AUTOSAR XML (schema 4-2-2)
package /LedBlinkerApplicationLayer/CompositionPackage
  composition sw component type RootComposition
    component ledBlinkerSWC: type=LedBlinkerSWC
    component serviceIoHwAb: type=IoHwAb
    connect serviceIoHwAb.Digital_LED1 -> ledBlinkerSWC.Digital_LED1
package /LedBlinkerApplicationLayer/ApplicationPackage
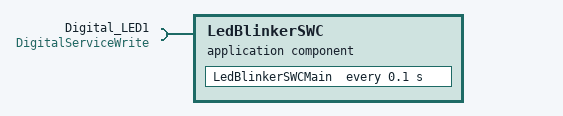
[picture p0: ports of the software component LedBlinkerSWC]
  application sw component type LedBlinkerSWC
    require port Digital_LED1: required-interface=DigitalServiceWrite
    behavior LedBlinkerSWCBehaviour: handle-termination-and-restart=NO-SUPPORT
      timing event LedBlinkerSWCMain_timingEvent_0_1: start-on-event=LedBlinkerSWCMain, period=0.1
      runnable LedBlinkerSWCMain: symbol=ledBlinkerSWCMain
        sync call LED1CallPoint: operation=Digital_LED1.Write, timeout=0.0
  swc implementation LedBlinkerSWCImpl: programming-language=C, vendor-id=0, behavior=LedBlinkerSWCBehaviour
    code-descriptors:
      code src: artifact-descriptors=autosar-engineering-object={short-label=artifactDescriptor, category=artifactDescriptorCategory}
    resource consumption resourceConsumption
package /LedBlinkerApplicationLayer/EcuExtract
  system LedBlinkerEcuExtract: category=ECU_EXTRACT, system-version=1
    system mapping ImplementationMappings
      sw-impl-mappings:
        swc to impl mapping MySWCMap: component-implementation=LedBlinkerSWCImpl, component=RootSwComposition.ledBlinkerSWC
        swc to impl mapping IoHwAbMap: component-implementation=IoHwAbImpl, component=RootSwComposition.serviceIoHwAb
    root-software-compositions:
      root sw composition prototype RootSwComposition: software-composition=RootComposition
package /LedBlinkerBSWConfiguration/Services/Os
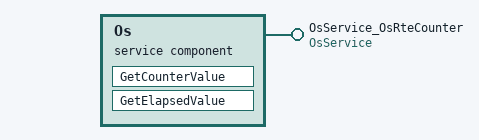
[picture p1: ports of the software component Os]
  service sw component type Os
    provide port OsService_OsRteCounter: provided-interface=OsService
    behavior OsBehavior: handle-termination-and-restart=NO-SUPPORT, port-api-option{port-defined-argument-value{value=CounterType:0, value-type=CounterType}, port=OsService_OsRteCounter}
      operation invoked event GetCounterValue_OsService_OsRteCounter_GetCounterValue: start-on-event=GetCounterValue, operation=OsService_OsRteCounter.GetCounterValue
      operation invoked event GetElapsedValue_OsService_OsRteCounter_GetElapsedValue: start-on-event=GetElapsedValue, operation=OsService_OsRteCounter.GetElapsedValue
      runnable GetCounterValue: symbol=Os_GetCounterValue
      runnable GetElapsedValue: symbol=Os_GetElapsedValue
  swc implementation OsImpl: programming-language=C, vendor-id=60, behavior=OsBehavior
    code-descriptors:
      code src: artifact-descriptors=autosar-engineering-object={short-label=artifactDescriptor, category=artifactDescriptorCategory}
    resource consumption resourceConsumption
package /LedBlinkerBSWConfiguration/Services/IoHwAb
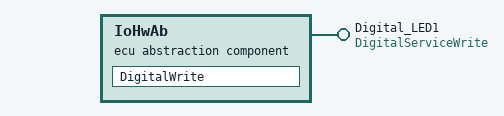
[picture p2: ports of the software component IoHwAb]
  ecu abstraction sw component type IoHwAb
    provide port Digital_LED1: provided-interface=DigitalServiceWrite
    behavior IoHwAbBehavior: handle-termination-and-restart=NO-SUPPORT, port-api-option{port-defined-argument-value{value=IoHwAb_SignalType_:0, value-type=IoHwAb_SignalType_}, port=Digital_LED1}
      operation invoked event DigitalWrite_Digital_LED1_Write: start-on-event=DigitalWrite, operation=Digital_LED1.Write
      runnable DigitalWrite: can-be-invoked-concurrently=true, symbol=IoHwAb_Digital_Write
  swc implementation IoHwAbImpl: programming-language=C, vendor-id=60, behavior=IoHwAbBehavior
    code-descriptors:
      code src: artifact-descriptors=autosar-engineering-object={short-label=artifactDescriptor, category=artifactDescriptorCategory}
    resource consumption resourceConsumption
package /LedBlinkerBSWConfiguration/Services/Det
  service sw component type Det
    behavior DetBehavior: handle-termination-and-restart=NO-SUPPORT
      runnable ReportError: symbol=Det_ReportError
  swc implementation DetImpl: programming-language=C, vendor-id=60, behavior=DetBehavior
    code-descriptors:
      code src: artifact-descriptors=autosar-engineering-object={short-label=artifactDescriptor, category=artifactDescriptorCategory}
    resource consumption resourceConsumption
package /LedBlinkerBSWConfiguration/Services/EcuM
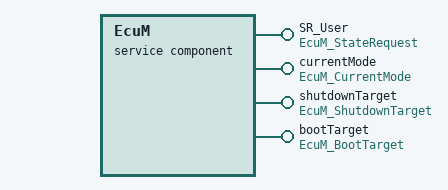
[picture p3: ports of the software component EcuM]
  service sw component type EcuM
    4 x provide port:
      SR_User: provided-interface=EcuM_StateRequest
      currentMode: provided-interface=EcuM_CurrentMode
      shutdownTarget: provided-interface=EcuM_ShutdownTarget
      bootTarget: provided-interface=EcuM_BootTarget
    behavior EcuMFixedBehavior: data-type-mapping=EcuMFixedTypeMappings, handle-termination-and-restart=NO-SUPPORT, port-api-option{port-defined-argument-value{value=EcuM_UserType:0, value-type=EcuM_UserType}, port=SR_User}
      9 x operation invoked event:
        RequestRUN_SR_User_RequestRUN: start-on-event=RequestRUN, operation=SR_User.RequestRUN
        ReleaseRUN_SR_User_ReleaseRUN: start-on-event=ReleaseRUN, operation=SR_User.ReleaseRUN
        RequestPOSTRUN_SR_User_RequestPOSTRUN: start-on-event=RequestPOSTRUN, operation=SR_User.RequestPOSTRUN
        ReleasePOSTRUN_SR_User_ReleasePOSTRUN: start-on-event=ReleasePOSTRUN, operation=SR_User.ReleasePOSTRUN
        SelectShutdownTarget_shutdownTarget_SelectShutdownTarget: start-on-event=SelectShutdownTarget, operation=shutdownTarget.SelectShutdownTarget
        GetShutdownTarget_shutdownTarget_GetShutdownTarget: start-on-event=GetShutdownTarget, operation=shutdownTarget.GetShutdownTarget
        GetLastShutdownTarget_shutdownTarget_GetLastShutdownTarget: start-on-event=GetLastShutdownTarget, operation=shutdownTarget.GetLastShutdownTarget
        SelectBootTarget_bootTarget_SelectBootTarget: start-on-event=SelectBootTarget, operation=bootTarget.SelectBootTarget
        GetBootTarget_bootTarget_GetBootTarget: start-on-event=GetBootTarget, operation=bootTarget.GetBootTarget
      10 x runnable:
        EcuM_MainFunction
          mode switch point modeSwitchPoint_EcuM_MainFunction_currentMode_currentMode: mode-group=currentMode.currentMode
        RequestRUN: can-be-invoked-concurrently=true, symbol=EcuM_RequestRUN
        ReleaseRUN: can-be-invoked-concurrently=true, symbol=EcuM_ReleaseRUN
        RequestPOSTRUN: can-be-invoked-concurrently=true, symbol=EcuM_RequestPOST_RUN
        ReleasePOSTRUN: can-be-invoked-concurrently=true, symbol=EcuM_ReleasePOST_RUN
        SelectShutdownTarget: can-be-invoked-concurrently=true, symbol=EcuM_SelectShutdownTarget
        GetShutdownTarget: can-be-invoked-concurrently=true, symbol=EcuM_GetShutdownTarget
        GetLastShutdownTarget: can-be-invoked-concurrently=true, symbol=EcuM_GetLastShutdownTarget
        SelectBootTarget: can-be-invoked-concurrently=true, symbol=EcuM_SelectBootTarget
        GetBootTarget: can-be-invoked-concurrently=true, symbol=EcuM_GetBootTarget
  swc implementation EcuMFixedImpl: programming-language=C, vendor-id=60, behavior=EcuMFixedBehavior
    code-descriptors:
      code src: artifact-descriptors=autosar-engineering-object={short-label=artifactDescriptor, category=artifactDescriptorCategory}
    resource consumption resourceConsumption
